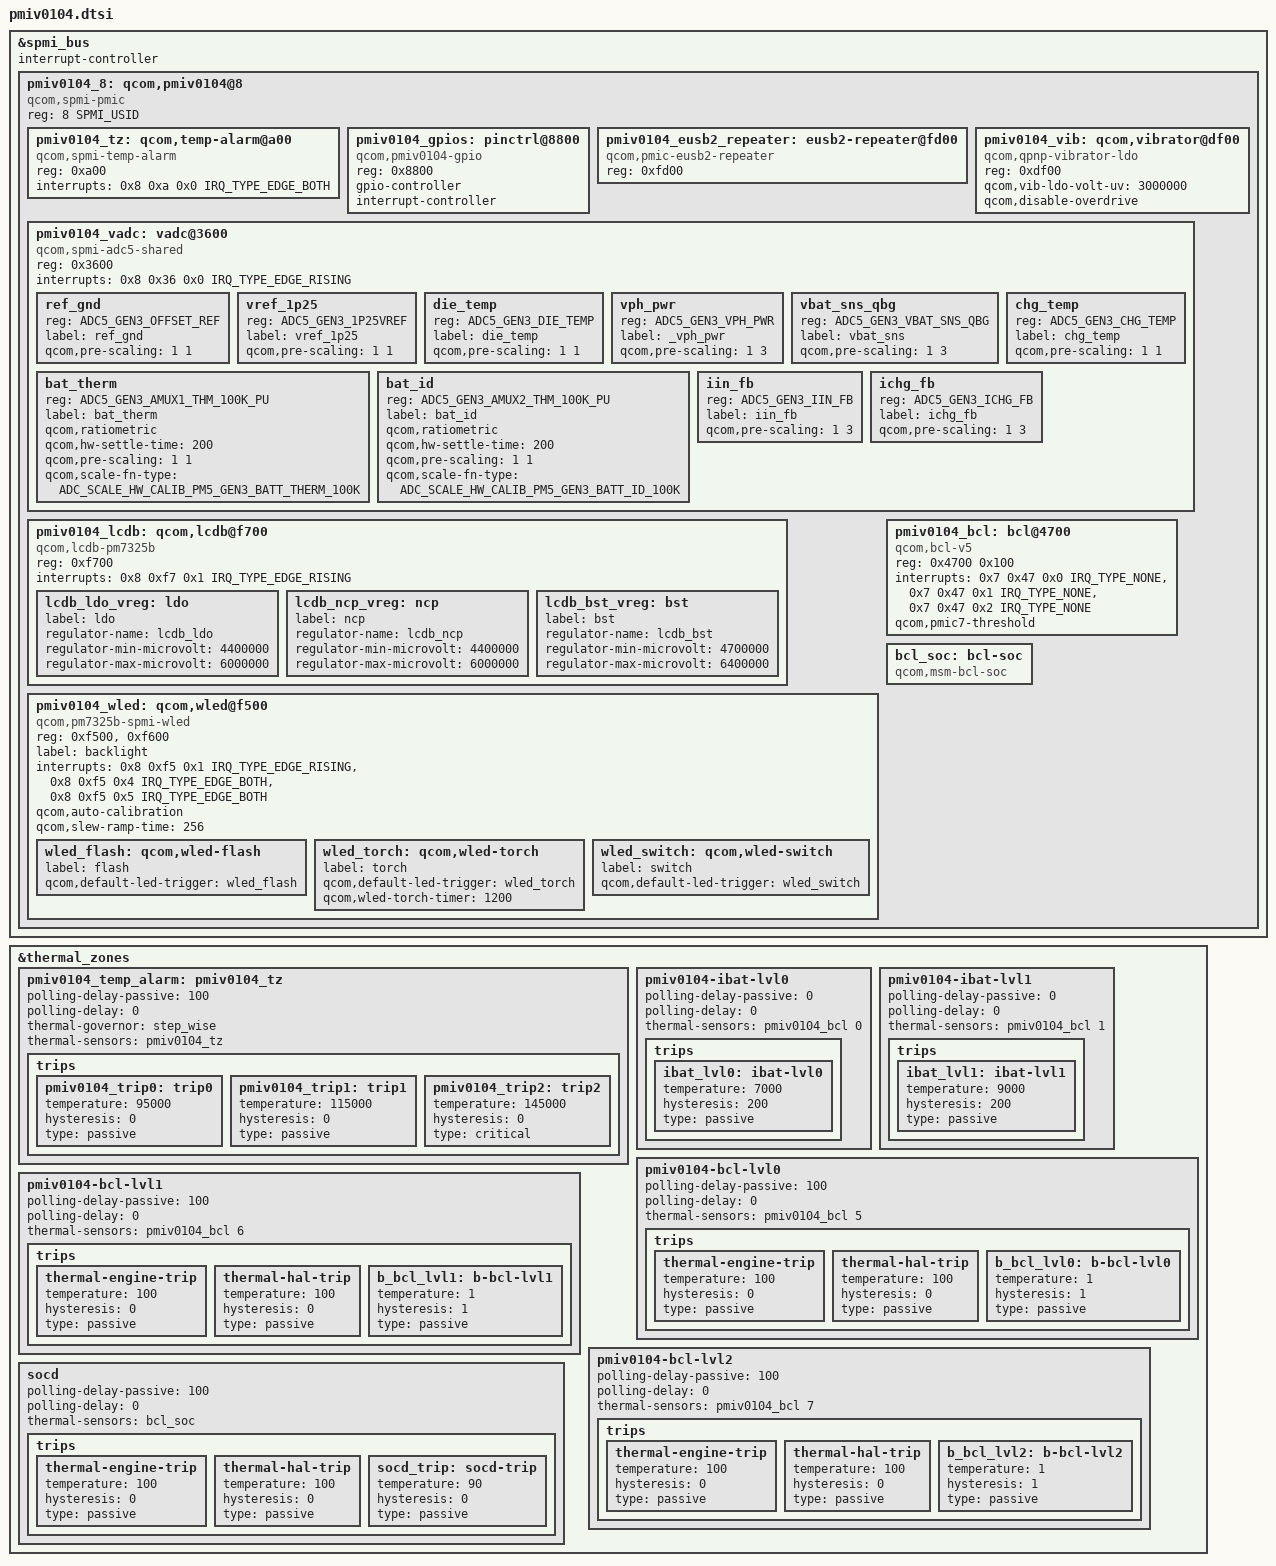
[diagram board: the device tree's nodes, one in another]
#include <dt-bindings/spmi/spmi.h>
#include <dt-bindings/interrupt-controller/irq.h>
#include <dt-bindings/iio/qcom,spmi-vadc.h>

&spmi_bus {
	#address-cells = <2>;
	#size-cells = <0>;
	interrupt-controller;
	#interrupt-cells = <4>;

	pmiv0104_8: qcom,pmiv0104@8 {
		compatible = "qcom,spmi-pmic";
		reg = <8 SPMI_USID>;
		#address-cells = <1>;
		#size-cells = <0>;

		pmiv0104_tz: qcom,temp-alarm@a00 {
			compatible = "qcom,spmi-temp-alarm";
			reg = <0xa00>;
			interrupts = <0x8 0xa 0x0 IRQ_TYPE_EDGE_BOTH>;
			#thermal-sensor-cells = <0>;
		};

		pmiv0104_gpios: pinctrl@8800 {
			compatible = "qcom,pmiv0104-gpio";
			reg = <0x8800>;
			gpio-controller;
			#gpio-cells = <2>;
			interrupt-controller;
			#interrupt-cells = <2>;
		};

		pmiv0104_eusb2_repeater: eusb2-repeater@fd00 {
			compatible = "qcom,pmic-eusb2-repeater";
			reg = <0xfd00>;
		};

		pmiv0104_vib: qcom,vibrator@df00 {
			compatible = "qcom,qpnp-vibrator-ldo";
			reg = <0xdf00>;
			qcom,vib-ldo-volt-uv = <3000000>;
			qcom,disable-overdrive;
		};

		pmiv0104_vadc:vadc@3600 {
			compatible = "qcom,spmi-adc5-shared";
			reg = <0x3600>;
			#address-cells = <1>;
			#size-cells = <0>;
			interrupts = <0x8 0x36 0x0 IRQ_TYPE_EDGE_RISING>;
			interrupt-names = "eoc-int-en-set";
			#io-channel-cells = <1>;

			/* Channel node */

			ref_gnd {
				reg = <ADC5_GEN3_OFFSET_REF>;
				label = "ref_gnd";
				qcom,pre-scaling = <1 1>;
			};

			vref_1p25 {
				reg = <ADC5_GEN3_1P25VREF>;
				label = "vref_1p25";
				qcom,pre-scaling = <1 1>;
			};

			die_temp {
				reg = <ADC5_GEN3_DIE_TEMP>;
				label = "die_temp";
				qcom,pre-scaling = <1 1>;
			};

			vph_pwr {
				reg = <ADC5_GEN3_VPH_PWR>;
				label = "_vph_pwr";
				qcom,pre-scaling = <1 3>;
			};

			vbat_sns_qbg {
				reg = <ADC5_GEN3_VBAT_SNS_QBG>;
				label = "vbat_sns";
				qcom,pre-scaling = <1 3>;
			};

			chg_temp {
				reg = <ADC5_GEN3_CHG_TEMP>;
				label = "chg_temp";
				qcom,pre-scaling = <1 1>;
			};

			bat_therm {
				reg = <ADC5_GEN3_AMUX1_THM_100K_PU>;
				label = "bat_therm";
				qcom,ratiometric;
				qcom,hw-settle-time = <200>;
				qcom,pre-scaling = <1 1>;
				qcom,scale-fn-type = <ADC_SCALE_HW_CALIB_PM5_GEN3_BATT_THERM_100K>;
			};

			bat_id {
				reg = <ADC5_GEN3_AMUX2_THM_100K_PU>;
				label = "bat_id";
				qcom,ratiometric;
				qcom,hw-settle-time = <200>;
				qcom,pre-scaling = <1 1>;
				qcom,scale-fn-type = <ADC_SCALE_HW_CALIB_PM5_GEN3_BATT_ID_100K>;
			};

			iin_fb {
				reg = <ADC5_GEN3_IIN_FB>;
				label = "iin_fb";
				qcom,pre-scaling = <1 3>;
			};

			ichg_fb {
				reg = <ADC5_GEN3_ICHG_FB>;
				label = "ichg_fb";
				qcom,pre-scaling = <1 3>;
			};
		};

		pmiv0104_lcdb: qcom,lcdb@f700 {
			compatible = "qcom,lcdb-pm7325b";
			#address-cells = <1>;
			#size-cells = <0>;
			reg = <0xf700>;
			interrupts = <0x8 0xf7 0x1 IRQ_TYPE_EDGE_RISING>;
			interrupt-names = "sc-irq";

			lcdb_ldo_vreg: ldo {
				label = "ldo";
				regulator-name = "lcdb_ldo";
				regulator-min-microvolt = <4400000>;
				regulator-max-microvolt = <6000000>;
			};

			lcdb_ncp_vreg: ncp {
				label = "ncp";
				regulator-name = "lcdb_ncp";
				regulator-min-microvolt = <4400000>;
				regulator-max-microvolt = <6000000>;
			};

			lcdb_bst_vreg: bst {
				label = "bst";
				regulator-name = "lcdb_bst";
				regulator-min-microvolt = <4700000>;
				regulator-max-microvolt = <6400000>;
			};
		};

		pmiv0104_wled: qcom,wled@f500 {
			compatible = "qcom,pm7325b-spmi-wled";
			reg = <0xf500>, <0xf600>;
			reg-names = "wled-ctrl-base", "wled-sink-base";
			label = "backlight";
			interrupts = <0x8 0xf5 0x1 IRQ_TYPE_EDGE_RISING>,
					<0x8 0xf5 0x4 IRQ_TYPE_EDGE_BOTH>,
					<0x8 0xf5 0x5 IRQ_TYPE_EDGE_BOTH>;
			interrupt-names = "ovp-irq", "pre-flash-irq",
					"flash-irq";
			qcom,auto-calibration;
			qcom,slew-ramp-time = <256>;

			wled_flash: qcom,wled-flash {
				label = "flash";
				qcom,default-led-trigger = "wled_flash";
			};

			wled_torch: qcom,wled-torch {
				label = "torch";
				qcom,default-led-trigger = "wled_torch";
				qcom,wled-torch-timer = <1200>;
			};

			wled_switch: qcom,wled-switch {
				label = "switch";
				qcom,default-led-trigger = "wled_switch";
			};
		};

		pmiv0104_bcl: bcl@4700 {
			compatible = "qcom,bcl-v5";
			reg = <0x4700 0x100>;
			interrupts = <0x7 0x47 0x0 IRQ_TYPE_NONE>,
					<0x7 0x47 0x1 IRQ_TYPE_NONE>,
					<0x7 0x47 0x2 IRQ_TYPE_NONE>;
			interrupt-names = "bcl-lvl0",
						"bcl-lvl1",
						"bcl-lvl2";
			qcom,pmic7-threshold;
			#thermal-sensor-cells = <1>;
		};

		bcl_soc:bcl-soc {
			compatible = "qcom,msm-bcl-soc";
			#thermal-sensor-cells = <0>;
		};
	};
};

&thermal_zones {
	pmiv0104_temp_alarm: pmiv0104_tz {
		polling-delay-passive = <100>;
		polling-delay = <0>;
		thermal-governor = "step_wise";
		thermal-sensors = <&pmiv0104_tz>;
		trips {
			pmiv0104_trip0: trip0 {
				temperature = <95000>;
				hysteresis = <0>;
				type = "passive";
			};

			pmiv0104_trip1: trip1 {
				temperature = <115000>;
				hysteresis = <0>;
				type = "passive";
			};

			pmiv0104_trip2: trip2 {
				temperature = <145000>;
				hysteresis = <0>;
				type = "critical";
			};
		};
	};

	pmiv0104-ibat-lvl0 {
		polling-delay-passive = <0>;
		polling-delay = <0>;
		thermal-sensors = <&pmiv0104_bcl 0>;

		trips {
			ibat_lvl0:ibat-lvl0 {
				temperature = <7000>;
				hysteresis = <200>;
				type = "passive";
			};
		};
	};

	pmiv0104-ibat-lvl1 {
		polling-delay-passive = <0>;
		polling-delay = <0>;
		thermal-sensors = <&pmiv0104_bcl 1>;

		trips {
			ibat_lvl1:ibat-lvl1 {
				temperature = <9000>;
				hysteresis = <200>;
				type = "passive";
			};
		};
	};

	pmiv0104-bcl-lvl0 {
		polling-delay-passive = <100>;
		polling-delay = <0>;
		thermal-sensors = <&pmiv0104_bcl 5>;

		trips {
			thermal-engine-trip {
				temperature = <100>;
				hysteresis = <0>;
				type = "passive";
			};

			thermal-hal-trip {
				temperature = <100>;
				hysteresis = <0>;
				type = "passive";
			};

			b_bcl_lvl0: b-bcl-lvl0 {
				temperature = <1>;
				hysteresis = <1>;
				type = "passive";
			};
		};
	};

	pmiv0104-bcl-lvl1 {
		polling-delay-passive = <100>;
		polling-delay = <0>;
		thermal-sensors = <&pmiv0104_bcl 6>;

		trips {
			thermal-engine-trip {
				temperature = <100>;
				hysteresis = <0>;
				type = "passive";
			};

			thermal-hal-trip {
				temperature = <100>;
				hysteresis = <0>;
				type = "passive";
			};

			b_bcl_lvl1: b-bcl-lvl1 {
				temperature = <1>;
				hysteresis = <1>;
				type = "passive";
			};
		};
	};

	pmiv0104-bcl-lvl2 {
		polling-delay-passive = <100>;
		polling-delay = <0>;
		thermal-sensors = <&pmiv0104_bcl 7>;

		trips {
			thermal-engine-trip {
				temperature = <100>;
				hysteresis = <0>;
				type = "passive";
			};

			thermal-hal-trip {
				temperature = <100>;
				hysteresis = <0>;
				type = "passive";
			};

			b_bcl_lvl2: b-bcl-lvl2 {
				temperature = <1>;
				hysteresis = <1>;
				type = "passive";
			};
		};
	};

	socd {
		polling-delay-passive = <100>;
		polling-delay = <0>;
		thermal-sensors = <&bcl_soc>;

		trips {
			thermal-engine-trip {
				temperature = <100>;
				hysteresis = <0>;
				type = "passive";
			};

			thermal-hal-trip {
				temperature = <100>;
				hysteresis = <0>;
				type = "passive";
			};

			socd_trip:socd-trip {
				temperature = <90>;
				hysteresis = <0>;
				type = "passive";
			};
		};
	};
};
